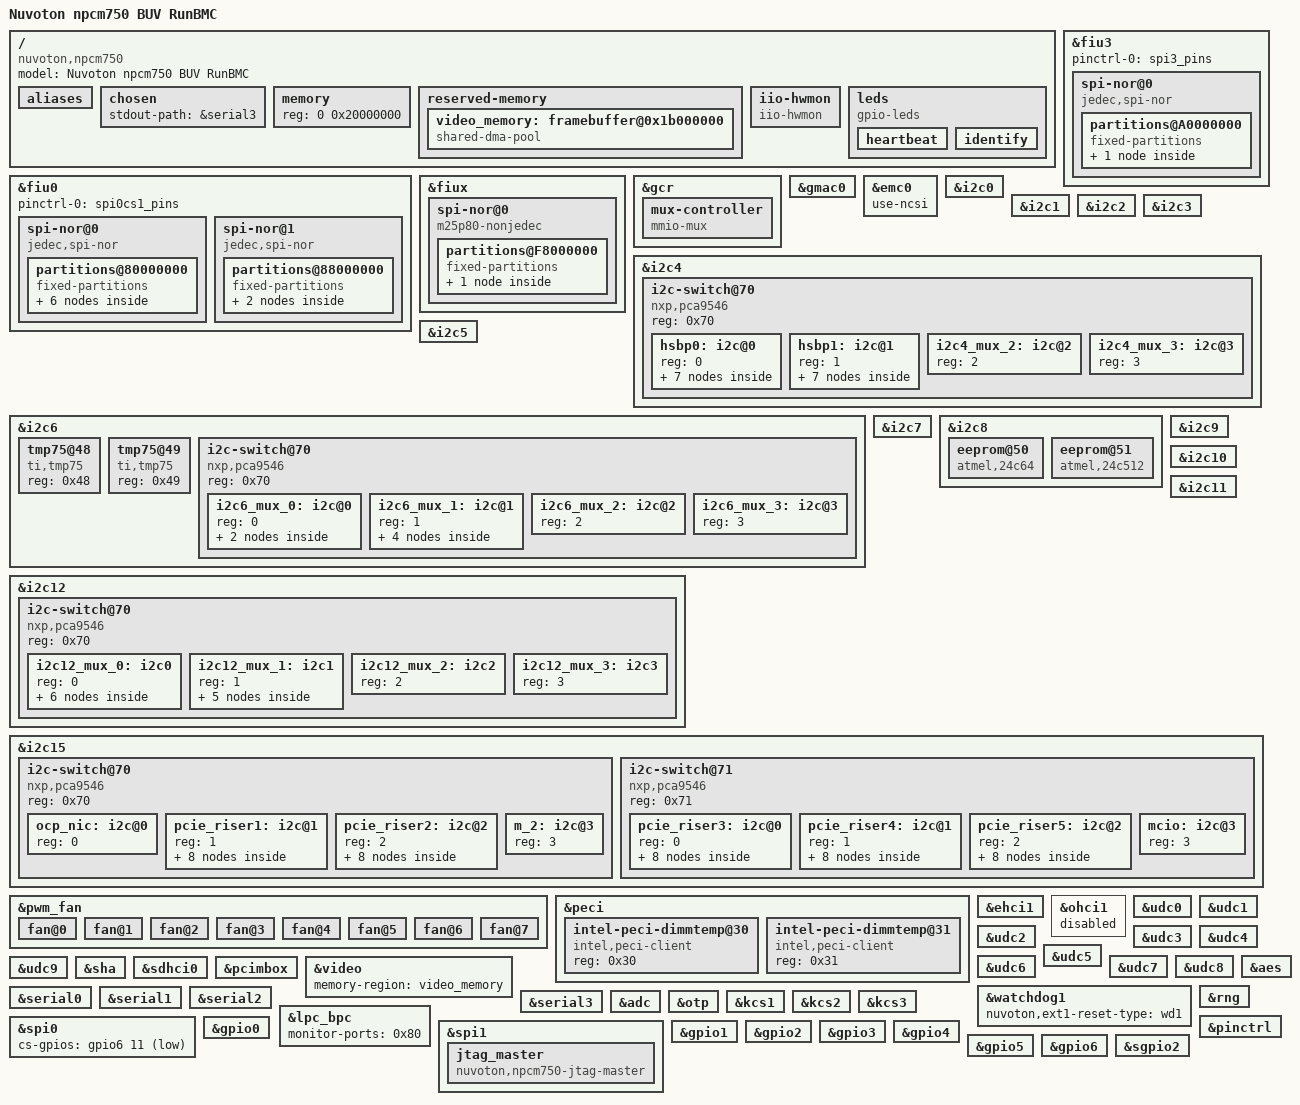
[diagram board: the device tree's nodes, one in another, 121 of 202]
// SPDX-License-Identifier: GPL-2.0
// Copyright (c) 2019 Nuvoton Technology kwliu@nuvoton.com

/dts-v1/;
#include "nuvoton-npcm750.dtsi"
#include "nuvoton-npcm750-buv-runbmc-pincfg.dtsi"

#include <dt-bindings/i2c/i2c.h>
#include <dt-bindings/gpio/gpio.h>

/ {
	model = "Nuvoton npcm750 BUV RunBMC";
	compatible = "nuvoton,npcm750";

	aliases {
                ethernet0 = &emc0;
                ethernet1 = &gmac0;
		serial0 = &serial0;
		serial1 = &serial1;
		serial2 = &serial2;
		serial3 = &serial3;
		udc0 = &udc0;
		udc1 = &udc1;
		udc2 = &udc2;
		udc3 = &udc3;
		udc4 = &udc4;
		udc5 = &udc5;
		udc6 = &udc6;
		udc7 = &udc7;
		udc8 = &udc8;
		udc9 = &udc9;
		emmc0 = &sdhci0;
		i2c0 = &i2c0;
		i2c1 = &i2c1;
		i2c2 = &i2c2;
		i2c3 = &i2c3;
		i2c4 = &i2c4;
		i2c5 = &i2c5;
		i2c6 = &i2c6;
		i2c7 = &i2c7;
		i2c8 = &i2c8;
		i2c9 = &i2c9;
		i2c10 = &i2c10;
		i2c11 = &i2c11;
		i2c12 = &i2c12;
		i2c13 = &i2c13;
		i2c15 = &i2c15;
		i2c16 = &hsbp0;
		i2c17 = &hsbp1;
		i2c18 = &i2c4_mux_2;
		i2c19 = &i2c4_mux_3;
		i2c20 = &i2c6_mux_0;
		i2c21 = &i2c6_mux_1;
		i2c22 = &i2c6_mux_2;
		i2c23 = &i2c6_mux_3;
		i2c24 = &i2c12_mux_0;
		i2c25 = &i2c12_mux_1;
		i2c26 = &i2c12_mux_2;
		i2c27 = &i2c12_mux_3;
		i2c28 = &ocp_nic;
		i2c29 = &pcie_riser1;
		i2c30 = &pcie_riser2;
		i2c31 = &m_2;
		i2c32 = &pcie_riser3;
		i2c33 = &pcie_riser4;
		i2c34 = &pcie_riser5;
		i2c35 = &mcio;
		i2c36 = &hsbp0_0;
		i2c37 = &hsbp0_1;
		i2c38 = &hsbp0_2;
		i2c39 = &hsbp0_3;
		i2c40 = &hsbp1_0;
		i2c41 = &hsbp1_1;
		i2c42 = &hsbp1_2;
		i2c43 = &hsbp1_3;
		i2c44 = &pcie_riser1_mux_0;
		i2c45 = &pcie_riser1_mux_1;
		i2c46 = &pcie_riser1_mux_2;
		i2c47 = &pcie_riser1_mux_3;
		i2c48 = &pcie_riser2_mux_0;
		i2c49 = &pcie_riser2_mux_1;
		i2c50 = &pcie_riser2_mux_2;
		i2c51 = &pcie_riser2_mux_3;
		i2c52 = &pcie_riser3_mux_0;
		i2c53 = &pcie_riser3_mux_1;
		i2c54 = &pcie_riser3_mux_2;
		i2c55 = &pcie_riser3_mux_3;
		i2c56 = &pcie_riser4_mux_0;
		i2c57 = &pcie_riser4_mux_1;
		i2c58 = &pcie_riser4_mux_2;
		i2c59 = &pcie_riser4_mux_3;
		i2c60 = &pcie_riser5_mux_0;
		i2c61 = &pcie_riser5_mux_1;
		i2c62 = &pcie_riser5_mux_2;
		i2c63 = &pcie_riser5_mux_3;
                spi0 = &spi0;
		spi1 = &spi1;
		fiu0 = &fiu0;
		fiu1 = &fiu3;
		fiu2 = &fiux;
	};

	chosen {
		stdout-path = &serial3;
	};

	memory {
		reg = <0 0x20000000>;
	};	

	reserved-memory {
		#address-cells = <1>;
		#size-cells = <1>;
		ranges;

        video_memory: framebuffer@0x1b000000 {
                      compatible = "shared-dma-pool";
                      reg = <0x1b000000 0x01800000>;
                      reusable;
                      linux,cma-default;
		};

	};

	iio-hwmon {
		compatible = "iio-hwmon";
		io-channels = <&adc 0>, <&adc 1>, <&adc 2>, <&adc 3>,
			<&adc 4>, <&adc 5>, <&adc 6>, <&adc 7>;
	};

	leds {
		compatible = "gpio-leds";
		heartbeat {
			label = "HB_LED";
			gpios = <&gpio3 14 1>;
		};

		identify {
			label = "UID_LED";
			gpios = <&gpio7 0 1>;
		};
	};
};
&fiu0 {
	pinctrl-names = "default";
	pinctrl-0 = <&spi0cs1_pins>;
	status = "okay";

	spi-nor@0 {
		compatible = "jedec,spi-nor";
		#address-cells = <1>;
		#size-cells = <1>;
		reg = <0>;
		spi-rx-bus-width = <2>;

		partitions@80000000 {
			compatible = "fixed-partitions";
			#address-cells = <1>;
			#size-cells = <1>;
			bmc@0{
				label = "bmc";
				reg = <0x000000 0x4000000>;
			};
			u-boot@0 {
				label = "u-boot";
				reg = <0x0000000 0xC0000>;
				read-only;
			};
			u-boot-env@100000{
				label = "u-boot-env";
				reg = <0x00100000 0x40000>;
			};
			kernel@200000 {
				label = "kernel";
				reg = <0x0200000 0x600000>;
			};
			rofs@800000 {
				label = "rofs";
				reg = <0x800000 0x3500000>;
			};
			rwfs@1d00000 {
				label = "rwfs";
				reg = <0x3d00000 0x300000>;
			};
		};
	};

	spi-nor@1 {
		compatible = "jedec,spi-nor";
		#address-cells = <1>;
		#size-cells = <1>;
		reg = <1>;
		npcm,fiu-rx-bus-width = <2>;

		partitions@88000000 {
			compatible = "fixed-partitions";
			#address-cells = <1>;
			#size-cells = <1>;
			spare1@0 {
				label = "spi0-cs1-spare1";
				reg = <0x0 0x800000>;
			};
			spare2@800000 {
				label = "spi0-cs1-spare2";
				reg = <0x800000 0x0>;
			};
		};
	};
};

&fiu3 {
	pinctrl-0 = <&spi3_pins>;
	status = "okay";

	spi-nor@0 {
		compatible = "jedec,spi-nor";
		#address-cells = <1>;
		#size-cells = <1>;
		reg = <0>;
		spi-rx-bus-width = <1>;

		partitions@A0000000 {
			compatible = "fixed-partitions";
			#address-cells = <1>;
			#size-cells = <1>;
			bios@0 {
				label = "bios";
				reg = <0x0 0x4000000>;
			};
		};
	};
};

&fiux {
	pinctrl-0 = <&spix_pins>;
	spix-mode;
	spi-nor@0 {
		compatible = "m25p80-nonjedec";
		spi-max-frequency = <5000000>;
		#address-cells = <1>;
		#size-cells = <1>;
		reg = <0>;
		spi-rx-bus-width = <1>;

		partitions@F8000000 {
			compatible = "fixed-partitions";
			#address-cells = <1>;
			#size-cells = <1>;
			xbios@0 {
				label = "xbios";
				reg = <0x0 0x2000000>;
			};
		};
	};
};

&gcr {
	mux-controller {
		compatible = "mmio-mux";
		#mux-control-cells = <1>;

		mux-reg-masks = <0x38 0x07>;
		idle-states = <1>;
	};
};

&gmac0 {
	phy-mode = "rgmii-id";
	snps,eee-force-disable;
	status = "okay";
};

&emc0 {
	status = "okay";
	use-ncsi;
};

&i2c0 {
	status = "okay";
};

&i2c1 {
	status = "okay";
};

&i2c2 {
	status = "okay";
};

&i2c3 {
	status = "okay";
};

&i2c4 {
	status = "okay";
	i2c-switch@70 {
		compatible = "nxp,pca9546";
		#address-cells = <1>;
		#size-cells = <0>;
		reg = <0x70>;

		/* i2c-16*/
		hsbp0: i2c@0 {
			#address-cells = <1>;
			#size-cells = <0>;
			reg = <0>;

			//BP0 FRU
			eeprom@51 {
				compatible = "atmel,24c64";
				reg = <0x51>;
				pagesize = <32>;
			};

			i2c-switch@71 {
				compatible = "nxp,pca9546";
				#address-cells = <1>;
				#size-cells = <0>;
				reg = <0x71>;

				/* i2c-36 */
				hsbp0_0: i2c@0 {
					//E3.S
					#address-cells = <1>;
					#size-cells = <0>;
					reg = <0>;
				};

				/* i2c-37 */
				hsbp0_1: i2c@1 {
					//E3.S
					#address-cells = <1>;
					#size-cells = <0>;
					reg = <1>;
				};

				/* i2c-38 */
				hsbp0_2: i2c@2 {
					//CPLD_UPGRADE
					#address-cells = <1>;
					#size-cells = <0>;
					reg = <2>;
				};

				/* i2c-39 */
				hsbp0_3: i2c@3 {
					#address-cells = <1>;
					#size-cells = <0>;
					reg = <3>;
					//PWR MON INA220
					ina220@40 {
						compatible = "ti,ina219";
						reg = <0x40>;
						shunt-resistor = <500>;
					};
				};
			};
		};

		/* i2c-17*/
		hsbp1: i2c@1 {
			#address-cells = <1>;
			#size-cells = <0>;
			reg = <1>;

			//BP1 FRU
			eeprom@51 {
				compatible = "atmel,24c64";
				reg = <0x51>;
				pagesize = <32>;
			};

			i2c-switch@71 {
				compatible = "nxp,pca9546";
				#address-cells = <1>;
				#size-cells = <0>;
				reg = <0x71>;

				/* i2c-40 */
				hsbp1_0: i2c@0 {
					//E3.S
					#address-cells = <1>;
					#size-cells = <0>;
					reg = <0>;
				};

				/* i2c-41 */
				hsbp1_1: i2c@1 {
					//E3.S
					#address-cells = <1>;
					#size-cells = <0>;
					reg = <1>;
				};

				/* i2c-42 */
				hsbp1_2: i2c@2 {
					//CPLD_UPGRADE
					#address-cells = <1>;
					#size-cells = <0>;
					reg = <2>;
				};

				/* i2c-43 */
				hsbp1_3: i2c@3 {
					#address-cells = <1>;
					#size-cells = <0>;
					reg = <3>;
					//PWR MON INA220
					ina220@40 {
						compatible = "ti,ina219";
						reg = <0x40>;
						shunt-resistor = <500>;
					};
				};
			};
		};
		/* i2c-18*/
		i2c4_mux_2: i2c@2 {
			#address-cells = <1>;
			#size-cells = <0>;
			reg = <2>;
		};
		/* i2c-19*/
		i2c4_mux_3: i2c@3 {
			#address-cells = <1>;
			#size-cells = <0>;
			reg = <3>;
		};
	};
};

&i2c5 {
	status = "okay";
};	

&i2c6 {
	status = "okay";
	tmp75@48 {
		compatible = "ti,tmp75";
		reg = <0x48>;
	};

	tmp75@49 {
		compatible = "ti,tmp75";
		reg = <0x49>;
	};

	i2c-switch@70 {
		compatible = "nxp,pca9546";
		#address-cells = <1>;
		#size-cells = <0>;
		reg = <0x70>;

		/* i2c-20 */
		i2c6_mux_0: i2c@0 {
			#address-cells = <1>;
			#size-cells = <0>;
			reg = <0>;

			tmp75@4a {
				compatible = "ti,tmp75";
				reg = <0x4a>;
			};
			/* HPM_EEPROM*/
			eeprom@51 {
				compatible = "atmel,24c64";
				reg = <0x51>;
				pagesize = <32>;
			};
		};
		/* i2c-21 */
		i2c6_mux_1: i2c@1 {
			#address-cells = <1>;
			#size-cells = <0>;
			reg = <1>;
            
			tmp75@4a {
				compatible = "ti,tmp75";
				reg = <0x4a>;
			};

			max31790@20 {
				compatible = "maxim,max31790";
				reg = <0x20>;
			};

			max31790@21 {
				compatible = "maxim,max31790";
				reg = <0x21>;
			};

			emc2302@2e {
				compatible = "emc2302";
				reg = <0x2e>;
			};
		};
		/* i2c-22 */
		i2c6_mux_2: i2c@2 {
			#address-cells = <1>;
			#size-cells = <0>;
			reg = <2>;
		};
		/* i2c-23 */
		i2c6_mux_3: i2c@3 {
			#address-cells = <1>;
			#size-cells = <0>;
			reg = <3>;
		};
	};
};

&i2c7 {
	status = "okay";
};

&i2c8 {
	status = "okay";

	/* SCM EEPROM*/
	eeprom@50 {
		compatible = "atmel,24c64";
		reg = <0x50>;
		pagesize = <32>;
	};

	/* RunBMC EEPROM*/
	eeprom@51 {
		compatible = "atmel,24c512";
		reg = <0x51>;
		pagesize = <128>;
	};
};

&i2c9 {
	status = "okay";
};

&i2c10 {
	status = "okay";
};

&i2c11 {
	status = "okay";
};

&i2c12 {
	status = "okay";
	i2c-switch@70 {
		compatible = "nxp,pca9546";
		#address-cells = <1>;
		#size-cells = <0>;
		reg = <0x70>;

		/* i2c-24 */
		i2c12_mux_0: i2c0 {
			#address-cells = <1>;
			#size-cells = <0>;
			reg = <0>;	

			/* XDPE19284B - PVCCIN VR */
			xdpe152c4@60 {
				compatible = "infineon,xdpe152c4";
				reg = <0x60>;
			};	
			
			/* XDPE19284B - PVCCFA EHV FIVRA */
			xdpe152c4@62 {
				compatible = "infineon,xdpe152c4";
				reg = <0x62>;
			};	
			
			/* XDPE19284B - PVCCD0 & D1 VR */
			xdpe152c4@76 {
				compatible = "infineon,xdpe152c4";
				reg = <0x76>;
			};	
			
			/* XDPE19284B - PVCCA EHV PVNN VR */
			xdpe152c4@74 {
				compatible = "infineon,xdpe152c4";
				reg = <0x74>;
			};

			//PWR MON INA219
			ina219@40 {
				compatible = "ti,ina219";
				reg = <0x40>;
				shunt-resistor = <500>;
			};		

			//PWR MON INA219
			ina219@41 {
				compatible = "ti,ina219";
				reg = <0x41>;
				shunt-resistor = <500>;
			};	
		};

		/* i2c-25 */
		i2c12_mux_1: i2c1 {
			#address-cells = <1>;
			#size-cells = <0>;
			reg = <1>;	

			/* XDPE19284B - PVCCIN VR */
			xdpe152c4@60 {
				compatible = "infineon,xdpe152c4";
				reg = <0x60>;
			};	
			
			/* XDPE19284B - PVCCFA EHV FIVRA */
			xdpe152c4@62 {
				compatible = "infineon,xdpe152c4";
				reg = <0x62>;
			};	
			
			/* XDPE19284B - PVCCD0 & D1 VR */
			xdpe152c4@76 {
				compatible = "infineon,xdpe152c4";
				reg = <0x76>;
			};	
			
			/* XDPE19284B - PVCCA EHV PVNN VR */
			xdpe152c4@74 {
				compatible = "infineon,xdpe152c4";
				reg = <0x74>;
			};

			//Voltage Sensor MAX1139
			adc_u74: voltage-sensor@35 {
				compatible = "maxim,max1139";
				reg = <0x35>;
				#io-channel-cells = <1>;
			};		
		};

		/* i2c-26 */
		i2c12_mux_2: i2c2 {
			#address-cells = <1>;
			#size-cells = <0>;
			reg = <2>;
		};

		/* i2c-27 */
		i2c12_mux_3: i2c3 {
			#address-cells = <1>;
			#size-cells = <0>;
			reg = <3>;
		};
	};
};

&i2c15 {
	status = "okay";

	i2c-switch@70 {
		compatible = "nxp,pca9546";
		#address-cells = <1>;
		#size-cells = <0>;
		reg = <0x70>;

		/* i2c-28 */
		ocp_nic: i2c@0 {
			#address-cells = <1>;
			#size-cells = <0>;
			reg = <0>;

			//OCP NIC P0 PE3
		};

		/* i2c-29 */
		/* Riser1 P0 PE0 */
		pcie_riser1: i2c@1 {
			#address-cells = <1>;
			#size-cells = <0>;
			reg = <1>;

			//Riser1 FRU
			eeprom@50 {
				compatible = "atmel,24c512";
				reg = <0x50>;
				pagesize = <128>;
			};

			//Riser1 MUX
			i2c-switch@70 {
				compatible = "nxp,pca9546";
				#address-cells = <1>;
				#size-cells = <0>;
				reg = <0x70>;

				/* i2c-44 */
				pcie_riser1_mux_0: i2c@0 {
					#address-cells = <1>;
					#size-cells = <0>;
					reg = <0>;

					//pcie slot1
				};

				/* i2c-45 */
				pcie_riser1_mux_1: i2c@1 {
					#address-cells = <1>;
					#size-cells = <0>;
					reg = <1>;

					//pcie slot2
				};

				/* i2c-46 */
				pcie_riser1_mux_2: i2c@2 {
					#address-cells = <1>;
					#size-cells = <0>;
					reg = <2>;

					//PWR MON INA220
					ina220@40 {
						compatible = "ti,ina220";
						reg = <0x40>;
						shunt-resistor = <500>;
					};
				};

				/* i2c-47 */
				pcie_riser1_mux_3: i2c@3 {
					#address-cells = <1>;
					#size-cells = <0>;
					reg = <3>;

					//TMP75
					tmp75@49 {
						compatible = "ti,tmp75";
						reg = <0x49>;
					};
				};
			};
		};

		/* i2c-30 */
		/* Riser2 P0 PE2 */
		pcie_riser2: i2c@2 {
			#address-cells = <1>;
			#size-cells = <0>;
			reg = <2>;

			//Riser2 FRU
			eeprom@50 {
				compatible = "atmel,24c512";
				reg = <0x50>;
				pagesize = <128>;
			};

			//Riser2 MUX
			i2c-switch@70 {
				compatible = "nxp,pca9546";
				#address-cells = <1>;
				#size-cells = <0>;
				reg = <0x70>;

				/* i2c-48 */
				pcie_riser2_mux_0: i2c@0 {
					#address-cells = <1>;
					#size-cells = <0>;
					reg = <0>;

					//pcie slot1
				};

				/* i2c-49 */
				pcie_riser2_mux_1: i2c@1 {
					#address-cells = <1>;
					#size-cells = <0>;
					reg = <1>;

					//pcie slot2
				};

				/* i2c-50 */
				pcie_riser2_mux_2: i2c@2 {
					#address-cells = <1>;
					#size-cells = <0>;
					reg = <2>;

					//PWR MON INA220
					ina220@40 {
						compatible = "ti,ina220";
						reg = <0x40>;
						shunt-resistor = <500>;
					};
				};

				/* i2c-51 */
				pcie_riser2_mux_3: i2c@3 {
					#address-cells = <1>;
					#size-cells = <0>;
					reg = <3>;

					//TMP75
					tmp75@49 {
						compatible = "ti,tmp75";
						reg = <0x49>;
					};
				};
			};
		};

		/* i2c-31 */
		m_2: i2c@3 {
			#address-cells = <1>;
			#size-cells = <0>;
			reg = <3>;

			//M.2 P0 PE1
		};
	};


	i2c-switch@71 {
		compatible = "nxp,pca9546";
		#address-cells = <1>;
		#size-cells = <0>;
		reg = <0x71>;

		/* i2c-32 */
		/* Riser3 P1 PE3 */
		pcie_riser3: i2c@0 {
			#address-cells = <1>;
			#size-cells = <0>;
			reg = <0>;

			//Riser3 FRU
			eeprom@50 {
				compatible = "atmel,24c512";
				reg = <0x50>;
				pagesize = <128>;
			};

			//Riser3 MUX
			i2c-switch@70 {
				compatible = "nxp,pca9546";
				#address-cells = <1>;
				#size-cells = <0>;
				reg = <0x70>;

				/* i2c-52 */
				pcie_riser3_mux_0: i2c@0 {
					#address-cells = <1>;
					#size-cells = <0>;
					reg = <0>;

					//pcie slot1
				};
			
				/* i2c-53 */
				pcie_riser3_mux_1: i2c@1 {
					#address-cells = <1>;
					#size-cells = <0>;
					reg = <1>;

					//pcie slot2
				};

				/* i2c-54 */
				pcie_riser3_mux_2: i2c@2 {
					#address-cells = <1>;
					#size-cells = <0>;
					reg = <2>;
	
					//PWR MON INA220
					ina220@40 {
						compatible = "ti,ina220";
						reg = <0x40>;
						shunt-resistor = <500>;
					};
				};

				/* i2c-55 */
				pcie_riser3_mux_3: i2c@3 {
					#address-cells = <1>;
					#size-cells = <0>;
					reg = <3>;

					//TMP75
					tmp75@49 {
						compatible = "ti,tmp75";
						reg = <0x49>;
					};
				};
			};
		};

		/* i2c-33 */
		/* Riser4 P1 PE0 */
		pcie_riser4: i2c@1 {
			#address-cells = <1>;
			#size-cells = <0>;
			reg = <1>;
			
			//Riser4 FRU
			eeprom@50 {
				compatible = "atmel,24c512";
				reg = <0x50>;
				pagesize = <128>;
			};
		
			//Riser4 MUX
			i2c-switch@70 {
				compatible = "nxp,pca9546";
				#address-cells = <1>;
				#size-cells = <0>;
				reg = <0x70>;

				/* i2c-56 */
				pcie_riser4_mux_0: i2c@0 {
					#address-cells = <1>;
					#size-cells = <0>;
					reg = <0>;

					//pcie slot1
				};
			
				/* i2c-57 */
				pcie_riser4_mux_1: i2c@1 {
					#address-cells = <1>;
					#size-cells = <0>;
					reg = <1>;

					//pcie slot2
				};

				/* i2c-58 */
				pcie_riser4_mux_2: i2c@2 {
					#address-cells = <1>;
					#size-cells = <0>;
					reg = <2>;

					//PWR MON INA220
					ina220@40 {
						compatible = "ti,ina220";
						reg = <0x40>;
						shunt-resistor = <500>;
					};
				};

				/* i2c-59 */
				pcie_riser4_mux_3: i2c@3 {
					#address-cells = <1>;
					#size-cells = <0>;
					reg = <3>;

					//TMP75
					tmp75@49 {
						compatible = "ti,tmp75";
						reg = <0x49>;
					};
				};

			};
		};

		/* i2c-34 */
		/* Riser5 P1 PE2 */
		pcie_riser5: i2c@2 {
			#address-cells = <1>;
			#size-cells = <0>;
			reg = <2>;

			//Riser5 FRU
			eeprom@50 {
				compatible = "atmel,24c512";
				reg = <0x50>;
				pagesize = <128>;
			};

			//Riser5 MUX
			i2c-switch@70 {
				compatible = "nxp,pca9546";
				#address-cells = <1>;
				#size-cells = <0>;
				reg = <0x70>;

				/* i2c-60 */
				pcie_riser5_mux_0: i2c@0 {
					#address-cells = <1>;
					#size-cells = <0>;
					reg = <0>;

					//pcie slot1
				};

				/* i2c-61 */
				pcie_riser5_mux_1: i2c@1 {
					#address-cells = <1>;
					#size-cells = <0>;
					reg = <1>;

					//pcie slot2
				};

				/* i2c-62 */
				pcie_riser5_mux_2: i2c@2 {
					#address-cells = <1>;
					#size-cells = <0>;
					reg = <2>;

					//PWR MON INA220
					ina220@40 {
						compatible = "ti,ina220";
						reg = <0x40>;
						shunt-resistor = <500>;
					};
				};	

				/* i2c-63 */
				pcie_riser5_mux_3: i2c@3 {
					#address-cells = <1>;
					#size-cells = <0>;
					reg = <3>;

					//TMP75
					tmp75@49 {
						compatible = "ti,tmp75";
						reg = <0x49>;
					};
				};
			};
		};

		/* i2c-35 */
		mcio: i2c@3 {
			#address-cells = <1>;
			#size-cells = <0>;
			reg = <3>;

			//MCIO P1 PE1
		};
	};
};

&pwm_fan {
	pinctrl-names = "default";
	pinctrl-0 = <&pwm0_pins &pwm1_pins
			&pwm2_pins &pwm3_pins
			&pwm4_pins &pwm5_pins
			&pwm6_pins &pwm7_pins
			&fanin0_pins &fanin1_pins
			&fanin2_pins &fanin3_pins
			&fanin4_pins &fanin5_pins
			&fanin6_pins &fanin7_pins
			&fanin8_pins &fanin9_pins
			&fanin10_pins &fanin11_pins
			&fanin12_pins &fanin13_pins
			&fanin14_pins &fanin15_pins>;
	status = "okay";
	fan@0 {
		reg = <0x00>;
		fan-tach-ch = /bits/ 8 <0x00 0x01>;
		cooling-levels = <127 255>;
		fan_filter_en;
	};
	fan@1 {
		reg = <0x01>;
		fan-tach-ch = /bits/ 8 <0x02 0x03>;
		cooling-levels = /bits/ 8 <127 255>;
		fan_filter_en;
	};
	fan@2 {
		reg = <0x02>;
		fan-tach-ch = /bits/ 8 <0x04 0x05>;
		cooling-levels = /bits/ 8 <127 255>;
		fan_filter_en;
	};
	fan@3 {
		reg = <0x03>;
		fan-tach-ch = /bits/ 8 <0x06 0x07>;
		cooling-levels = /bits/ 8 <127 255>;
	};
	fan@4 {
		reg = <0x04>;
		fan-tach-ch = /bits/ 8 <0x08 0x09>;
		cooling-levels = /bits/ 8 <127 255>;
	};
	fan@5 {
		reg = <0x05>;
		fan-tach-ch = /bits/ 8 <0x0A 0x0B>;
		cooling-levels = /bits/ 8 <127 255>;
	};
	fan@6 {
		reg = <0x06>;
		fan-tach-ch = /bits/ 8 <0x0C 0x0D>;
		cooling-levels = /bits/ 8 <127 255>;
	};
	fan@7 {
		reg = <0x07>;
		fan-tach-ch = /bits/ 8 <0x0E 0x0F>;
		cooling-levels = /bits/ 8 <127 255>;
	};
};

&peci {
	cmd-timeout-ms = <1000>;
	pull-down = <0>;
	host-neg-bit-rate = <15>;
	status = "okay";

	intel-peci-dimmtemp@30 {
		compatible = "intel,peci-client";
		reg = <0x30>;
	};
	intel-peci-dimmtemp@31 {
		compatible = "intel,peci-client";
		reg = <0x31>;
	};
};

&ehci1 {
	status = "okay";
};

&ohci1 {
	status = "disable";
};

&udc0 {
	status = "okay";
};

&udc1 {
	status = "okay";
};

&udc2 {
	status = "okay";
};

&udc3 {
	status = "okay";
};

&udc4 {
	status = "okay";
};

&udc5 {
	status = "okay";
};

&udc6 {
	status = "okay";
};

&udc7 {
	status = "okay";
};

&udc8 {
	status = "okay";
};

&udc9 {
	status = "okay";
};

&aes {
	status = "okay";
};

&sha {
	status = "okay";
};


&sdhci0 {
	status = "okay";
};

&pcimbox {
	status = "okay";
};

&video {
       memory-region = <&video_memory>;
       status = "okay";
};

&watchdog1 {
	nuvoton,ext1-reset-type = "wd1";
	status = "okay";
};

&rng {
	status = "okay";
};

&serial0 {
	status = "okay";
};

&serial1 {
	status = "okay";
};

&serial2 {
	status = "okay";
};

&serial3 {
	status = "okay";
};

&adc {
	#io-channel-cells = <1>;
	status = "okay";
};

&otp {
	status = "okay";
};

&kcs1 {
	status = "okay";
};

&kcs2 {
	status = "okay";
};

&kcs3 {
	status = "okay";
};

&lpc_bpc {
	monitor-ports = <0x80>;
	status = "okay";
};

&spi0 {
	cs-gpios = <&gpio6 11 GPIO_ACTIVE_LOW>;
	status = "okay";
};

&spi1 {
	cs-gpios = <&gpio6 0 GPIO_ACTIVE_HIGH>;
	pinctrl-names = "default";
	pinctrl-0 = <&gpio17_pins &gpio18o_pins
				&gpio19ol_pins>;
	status = "okay";
	jtag_master {
		compatible = "nuvoton,npcm750-jtag-master";
		spi-max-frequency = <25000000>;
		reg = <0>;

		pinctrl-names = "pspi", "gpio";
		pinctrl-0 = <&pspi2_pins>;
		pinctrl-1 = <&gpio17_pins &gpio18o_pins
				&gpio19ol_pins>;

		tck-gpios = <&gpio0 19 GPIO_ACTIVE_HIGH>;
		tdi-gpios = <&gpio0 18 GPIO_ACTIVE_HIGH>;
		tdo-gpios = <&gpio0 17 GPIO_ACTIVE_HIGH>;
		tms-gpios = <&gpio0 16 GPIO_ACTIVE_HIGH>;
		status = "okay";
	};
};

&pinctrl {
		pinctrl-names = "default";
		pinctrl-0 = <
				&ddc_pins
				&wdog1_pins
				&wdog2_pins
				&gpio1o_pins
				&gpio138o_pins
				&gpio139o_pins
				&gpio89o_pins
				&gpio143o_pins
				&gpio9o_pins
				&gpio231o_pins
				&gpio140o_pins
				&gpio142o_pins
				&gpio90o_pins
				&gpio88o_pins
				&gpio141o_pins
				&gpio87o_pins
				&gpio11o_pins
				&gpio24o_pins
				&gpio137o_pins
				&gpio25o_pins
				&gpio84_pins
				&gpio85_pins
				&gpio122_pins
				&gpio124_pins
				&gpio125_pins
				&gpio126_pins
				&gpio225ol_pins
				&gpio227ol_pins
				&gpio4_pins
				&gpio5_pins
				&gpio6_pins
				&gpio7_pins				
				>;
};
&gpio0 {
 	gpio-line-names =
 	/*0-31*/
	/*0-7*/
 	"","RST_BMC_SGPIO","","","","","","",
	/*8-15*/
 	"CPLD_PWRBRK","CPU0_MEMHOT","","JTAG_MUX_SEL","","","","",
	/*16-23*/
 	"","","","","","","IRQ_CPU1_MEM_VRHOT","RST_BTN_BMC_OUT",
	/*24-31*/
	"","CPU1_MEMHOT","","","","","","";	
 };

&gpio1 {
 	gpio-line-names =
 	/*32-63*/
	/*32-39*/
 	"","","","","","","","",
 	/*40-47*/
	"CPU1_MEMHOT_IN","","","","","","","",
 	/*48-55*/
	"","","","PRDY_N","","PREQ_N","","DBP_HOOK3_CPU_FBRK_OUT",
	/*56-63*/
	"","","","","","","","";		
 };

&gpio2 {
	gpio-line-names =
	/*64-95*/
	/*64-71*/
	"","","","PSU0_PRESENT","","PSU1_PRESENT","I3C_SPDMUX_SELECT0","",
	/*72-79*/
	"SPI_BIOS_MUXA_SEL","SPI_BIOS_MUXB_SEL","","","NCSI_OCP_CLK_EN","NCSI_BMC_CLK_EN","","BMC_READY",
	/*80-87*/								
	"CPU0_PROCHOT_CPLD","CPU1_PROCHOT_CPLD","IRQ_BMC_CPU0_NMI_OUT","CPU0_THERMTRIP","","","","",
	/*88-95*/
	"PCH_SMI_ACTIVE_N","","","PS_PWROK","","BMC_PWR_BTN_OUT","","";
};

&gpio3 {
	gpio-line-names =
	/*96-127*/
	/*96-103*/	
	"","","","","","","","",
	/*104-111*/	
	"","","","","","","","",
	/*112-119*/	
	"","","","","","","","",
	/*120-127*/
	"CPU0_MEMHOT_IN","","","","","CPU_CATERR","","";
};

&gpio4 {
	gpio-line-names =
	/*128-159*/
	/*128-135*/
	"","","","","","","","",
	/*136-143*/
	"SPI_BMC_PROG_CPLD_R_EN","","","","CPU0_BMCINIT","CPU1_BMCINIT","","FM_SPD_SWITCH_CTRL",
	/*144-151*/
	"IRQ_BMC_CPU1_NMI_OUT","CPU1_THERMTRIP","I3C_SPDMUX_SELECT1","","","","","",
	/*152-159*/
	"","","","","","","","";
};

&gpio5 {
	gpio-line-names =
	/*160-191*/
	/*160-167*/
	"","","","","","","","",
	/*168-175*/
	"","BMC_WAKE","","","","","","",
	/*176-183*/
	"","","","","","","","",
	/*184-191*/
	"","","","RST_CPU0_RTCRST_PLD","","","","";
};

&gpio6 {
	gpio-line-names =
	/*192-223*/
	/*192-199*/
	"","","","","","","","",
	/*200-207*/
	"","","","","","","","",
	/*208-215*/
	"","","","CPU_ERR0","","CPU_ERR1","","CPU_ERR2",
	/*216-223*/
	"","","","","","","ASSERT_CPU0_PROCHOT","ASSERT_CPU1_PROCHOT"; 
};


&sgpio2 {
    status = "okay";
    bus-frequency = <1000000>;
    nin_gpios = <64>;
    nout_gpios = <64>;
    gpio-line-names = "LED_PORT80_0_N","LED_PORT80_1_N","LED_PORT80_2_N","LED_PORT80_3_N","LED_PORT80_4_N","LED_PORT80_5_N","LED_PORT80_6_N","LED_PORT80_7_N",
    "CPLD_JTAG_OE_R_N","RST_PE_SLOT_I2C_MUX_N","","","","","","",
    "","","","","","","","",
    "","","","","","","","",
    "","","","","","","","",
    "","","","","","","","",
    "","","","","","","","",
    "","","","","","","","",
    "FAN1_INSTALL_R_N","MLB_BRD_REV_ID1","MLB_BRD_REV_ID0","MLB_BRD_SKU_ID3","MLB_BRD_SKU_ID2","MLB_BRD_SKU_ID1","MLB_BRD_SKU_ID0","FM_TPM_PRSNT_N",
    "PE_M2_ALERT_R_N","PASSWORD_CLEAR_N","IRQ_PSYS_CRIT_N","FAN6_INSTALL_R_N","FAN5_INSTALL_R_N","FAN4_INSTALL_R_N","FAN3_INSTALL_R_N","FAN2_INSTALL_R_N",
    "RISER4_ID2_R","RISER4_ID1_R","RISER4_ID0_R","RISER5_ID2_R","RISER5_ID1_R","RISER5_ID0_R","","",
    "RISER1_ID1_R","RISER1_ID0_R","RISER2_ID2_R","RISER2_ID1_R","RISER2_ID0_R","RISER3_ID2_R","RISER3_ID1_R","RISER3_ID0_R",
    "PRSNT_RISER3_SLOT1_N","PRSNT_RISER4_SLOT3_N","PRSNT_RISER4_SLOT2_N","PRSNT_RISER4_SLOT1_N","PRSNT_RISER5_SLOT3_N","PRSNT_RISER5_SLOT2_N","PRSNT_RISER5_SLOT1_N","RISER1_ID2_R",
    "PRSNT_RISER1_SLOT3_N","PRSNT_RISER1_SLOT2_N","PRSNT_RISER1_SLOT1_N","PRSNT_RISER2_SLOT3_N","PRSNT_RISER2_SLOT2_N","PRSNT_RISER2_SLOT1_N","PRSNT_RISER3_SLOT3_N","PRSNT_RISER3_SLOT2_N",
    "CPU1_CD_INIT_ERROR","PWRGD_CPU0_S0_PWROK_R","PWRGD_CPU1_S0_PWROK_R","RISER1_PRSNT_N_R","RISER2_PRSNT_N_R","RISER3_PRSNT_N_R","RISER4_PRSNT_N_R","RISER5_PRSNT_N_R",
    "CPU0_PRSNT_N","CPU1_PRSNT_N","CPU0_PWR_GOOD","CPU1_PWR_GOOD","PGD_SYS_PWROK","","","CPU0_CD_INIT_ERROR";
};

